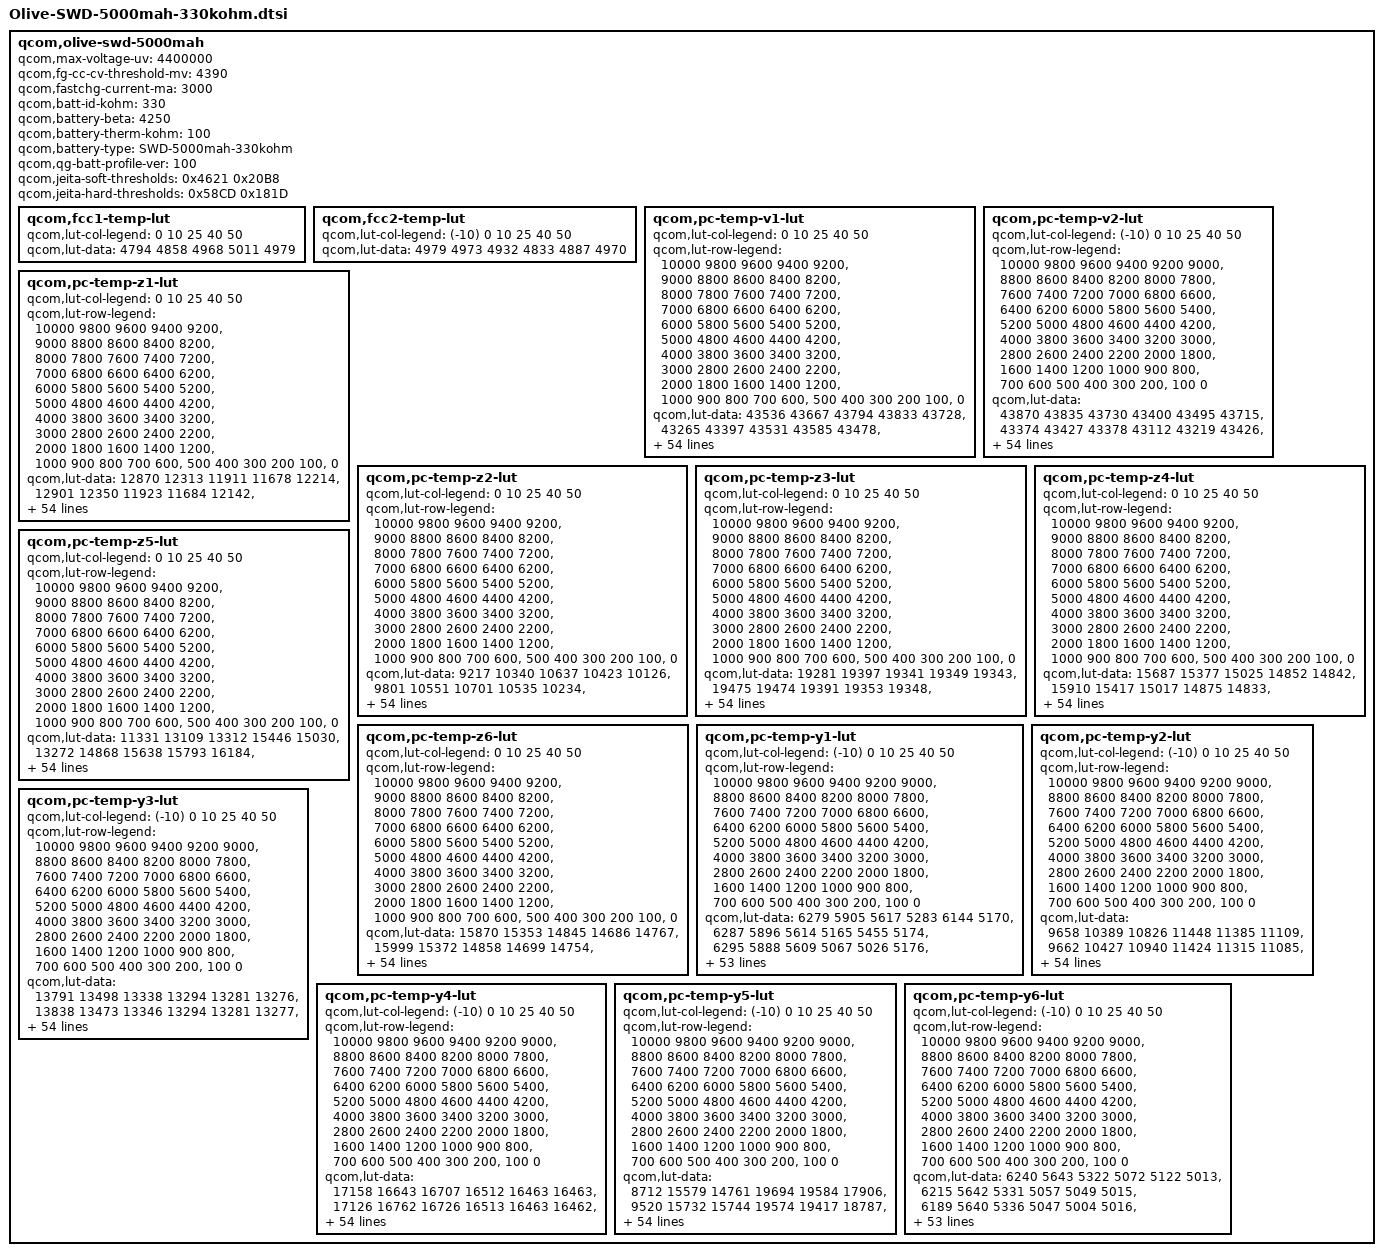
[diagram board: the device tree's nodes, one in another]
/* Copyright (c) 2018, The Linux Foundation. All rights reserved.
 * Copyright (C) 2021 XiaoMi, Inc.
 *
 * This program is free software; you can redistribute it and/or modify
 * it under the terms of the GNU General Public License version 2 and
 * only version 2 as published by the Free Software Foundation.
 *
 * This program is distributed in the hope that it will be useful,
 * but WITHOUT ANY WARRANTY; without even the implied warranty of
 * MERCHANTABILITY or FITNESS FOR A PARTICULAR PURPOSE.  See the
 * GNU General Public License for more details.
 */

qcom,olive-swd-5000mah {
	/* Peony-SWD-5000mah-300kohm_Master_2018.12.27 */
	qcom,max-voltage-uv = <4400000>;
	qcom,fg-cc-cv-threshold-mv = <4390>;
	qcom,fastchg-current-ma = <3000>;
	qcom,batt-id-kohm = <330>;
	qcom,battery-beta = <4250>;
	qcom,battery-therm-kohm = <100>;
	qcom,battery-type =
		"SWD-5000mah-330kohm";
	qcom,qg-batt-profile-ver = <100>;

/*	qcom,jeita-fcc-ranges = <0   50   400000
				 51  100  1200000
				 101 150  1950000
				 151 450  2000000
				 451 550  1000000
				 551 600  0>;
	qcom,jeita-fv-ranges =  <0   50   4400000
				 51  100  4400000
				 101 150  4400000
				 151 450  4400000
				 451 550  4100000
				 551 600  4100000>;*/

	/* COOL = 15 DegC, WARM = 45 DegC */
	qcom,jeita-soft-thresholds = <0x4621 0x20B8>;
	/* COLD = 0 DegC, HOT = 55 DegC */
	qcom,jeita-hard-thresholds = <0x58CD 0x181D>;

	qcom,fcc1-temp-lut {
		qcom,lut-col-legend = <0 10 25 40 50>;
		qcom,lut-data = <4794 4858 4968 5011 4979>;
	};

	qcom,fcc2-temp-lut {
		qcom,lut-col-legend = <(-10) 0 10 25 40 50>;
		qcom,lut-data = <4979 4973 4932 4833 4887 4970>;
	};

	qcom,pc-temp-v1-lut {
		qcom,lut-col-legend = <0 10 25 40 50>;
		qcom,lut-row-legend = <10000 9800 9600 9400 9200>,
			<9000 8800 8600 8400 8200>,
			<8000 7800 7600 7400 7200>,
			<7000 6800 6600 6400 6200>,
			<6000 5800 5600 5400 5200>,
			<5000 4800 4600 4400 4200>,
			<4000 3800 3600 3400 3200>,
			<3000 2800 2600 2400 2200>,
			<2000 1800 1600 1400 1200>,
			<1000 900 800 700 600>,
			<500 400 300 200 100>,
			<0>;
		qcom,lut-data = <43536 43667 43794 43833 43728>,
			<43265 43397 43531 43585 43478>,
			<42998 43141 43275 43332 43235>,
			<42747 42894 43027 43084 42994>,
			<42516 42655 42785 42843 42758>,
			<42297 42423 42546 42605 42524>,
			<42085 42198 42311 42369 42293>,
			<41878 41982 42081 42136 42064>,
			<41679 41772 41856 41906 41838>,
			<41490 41569 41637 41679 41613>,
			<41315 41380 41426 41454 41391>,
			<41124 41191 41231 41236 41173>,
			<40890 40983 41034 41022 40958>,
			<40630 40759 40810 40812 40752>,
			<40375 40528 40566 40601 40550>,
			<40115 40270 40340 40400 40357>,
			<39907 40020 40133 40209 40176>,
			<39775 39859 39948 40029 40002>,
			<39673 39762 39805 39862 39838>,
			<39568 39663 39691 39715 39684>,
			<39463 39522 39552 39560 39515>,
			<39353 39350 39347 39366 39310>,
			<39221 39165 39127 39152 39097>,
			<39071 38933 38948 38966 38917>,
			<38924 38735 38787 38796 38760>,
			<38772 38645 38664 38652 38629>,
			<38629 38591 38576 38545 38519>,
			<38539 38540 38503 38455 38423>,
			<38478 38486 38428 38370 38337>,
			<38431 38436 38356 38289 38260>,
			<38392 38388 38293 38217 38191>,
			<38362 38343 38237 38154 38125>,
			<38332 38301 38188 38098 38066>,
			<38305 38264 38145 38047 38010>,
			<38279 38231 38108 38004 37959>,
			<38251 38198 38071 37961 37907>,
			<38224 38170 38036 37916 37854>,
			<38187 38135 37998 37867 37797>,
			<38124 38073 37940 37803 37724>,
			<38038 37979 37852 37715 37629>,
			<37949 37874 37749 37614 37524>,
			<37856 37752 37634 37502 37409>,
			<37732 37612 37501 37371 37278>,
			<37557 37441 37336 37209 37117>,
			<37394 37274 37189 37078 37000>,
			<37284 37229 37091 36992 36923>,
			<37247 37188 37066 36963 36901>,
			<37214 37162 37044 36945 36879>,
			<37183 37131 37026 36925 36856>,
			<37127 37075 36970 36851 36765>,
			<36899 36833 36696 36555 36437>,
			<36452 36383 36253 36105 35987>,
			<35876 35802 35673 35517 35403>,
			<35097 35015 34875 34711 34600>,
			<33863 33780 33619 33443 33335>,
			<30000 30000 30000 30000 30000>;
	};

	qcom,pc-temp-v2-lut {
		qcom,lut-col-legend = <(-10) 0 10 25 40 50>;
		qcom,lut-row-legend = <10000 9800 9600 9400 9200 9000>,
			<8800 8600 8400 8200 8000 7800>,
			<7600 7400 7200 7000 6800 6600>,
			<6400 6200 6000 5800 5600 5400>,
			<5200 5000 4800 4600 4400 4200>,
			<4000 3800 3600 3400 3200 3000>,
			<2800 2600 2400 2200 2000 1800>,
			<1600 1400 1200 1000 900 800>,
			<700 600 500 400 300 200>,
			<100 0>;
		qcom,lut-data = <43870 43835 43730 43400 43495 43715>,
			<43374 43427 43378 43112 43219 43426>,
			<42942 43062 43058 42841 42956 43153>,
			<42589 42748 42773 42587 42705 42895>,
			<42298 42476 42524 42352 42468 42654>,
			<42028 42227 42285 42125 42237 42418>,
			<41705 41995 42047 41899 42007 42182>,
			<41426 41778 41813 41677 41780 41948>,
			<41356 41557 41569 41463 41557 41718>,
			<41346 41320 41296 41262 41336 41491>,
			<41332 41126 41071 41069 41119 41267>,
			<41143 41021 40946 40866 40913 41049>,
			<40763 40931 40852 40629 40717 40834>,
			<40390 40740 40688 40387 40520 40627>,
			<39972 40286 40318 40179 40307 40424>,
			<39618 39880 39954 40000 40102 40229>,
			<39405 39694 39778 39837 39926 40047>,
			<39235 39556 39659 39674 39773 39873>,
			<39044 39390 39521 39516 39620 39705>,
			<38824 39196 39346 39361 39454 39550>,
			<38641 38994 39154 39179 39269 39384>,
			<38520 38775 38955 38969 39065 39173>,
			<38425 38559 38751 38772 38854 38940>,
			<38345 38411 38572 38614 38676 38751>,
			<38277 38300 38417 38481 38534 38597>,
			<38216 38212 38282 38365 38415 38466>,
			<38159 38146 38168 38266 38312 38353>,
			<38105 38094 38071 38176 38218 38254>,
			<38052 38044 38001 38094 38133 38163>,
			<38000 37998 37952 38019 38056 38079>,
			<37948 37955 37914 37951 37989 38004>,
			<37896 37913 37880 37888 37926 37939>,
			<37843 37872 37850 37831 37867 37881>,
			<37788 37830 37820 37781 37805 37817>,
			<37734 37786 37791 37740 37739 37746>,
			<37678 37741 37758 37694 37666 37669>,
			<37617 37693 37715 37642 37587 37575>,
			<37555 37641 37656 37583 37507 37469>,
			<37483 37579 37585 37513 37431 37377>,
			<37399 37506 37498 37431 37356 37303>,
			<37309 37420 37393 37337 37275 37229>,
			<37219 37313 37278 37223 37180 37136>,
			<37131 37189 37149 37097 37071 37027>,
			<37052 37061 37027 36984 36934 36896>,
			<36982 36939 36918 36897 36837 36789>,
			<36904 36853 36826 36835 36798 36745>,
			<36861 36822 36781 36811 36782 36734>,
			<36809 36788 36733 36779 36764 36717>,
			<36735 36744 36675 36718 36726 36679>,
			<36612 36671 36574 36509 36588 36537>,
			<36359 36492 36369 36129 36226 36179>,
			<35943 36078 35963 35574 35708 35660>,
			<35351 35482 35346 34842 35040 34988>,
			<34480 34652 34500 33775 34126 34066>,
			<33086 33342 33193 32461 32685 32546>,
			<28428 29503 28960 27673 27665 28669>;
	};

	qcom,pc-temp-z1-lut {
		qcom,lut-col-legend = <0 10 25 40 50>;
		qcom,lut-row-legend = <10000 9800 9600 9400 9200>,
			<9000 8800 8600 8400 8200>,
			<8000 7800 7600 7400 7200>,
			<7000 6800 6600 6400 6200>,
			<6000 5800 5600 5400 5200>,
			<5000 4800 4600 4400 4200>,
			<4000 3800 3600 3400 3200>,
			<3000 2800 2600 2400 2200>,
			<2000 1800 1600 1400 1200>,
			<1000 900 800 700 600>,
			<500 400 300 200 100>,
			<0>;
		qcom,lut-data = <12870 12313 11911 11678 12214>,
			<12901 12350 11923 11684 12142>,
			<12907 12347 11930 11688 12066>,
			<12906 12333 11928 11687 11996>,
			<12897 12327 11921 11680 11930>,
			<12886 12317 11914 11673 11871>,
			<12883 12307 11904 11668 11817>,
			<12883 12307 11896 11664 11773>,
			<12883 12308 11892 11662 11740>,
			<12877 12306 11890 11660 11712>,
			<12851 12295 11888 11659 11680>,
			<12827 12280 11888 11661 11642>,
			<12817 12264 11888 11664 11620>,
			<12806 12246 11883 11664 11616>,
			<12794 12235 11870 11653 11612>,
			<12768 12233 11863 11644 11613>,
			<12742 12233 11864 11645 11621>,
			<12732 12236 11866 11648 11635>,
			<12724 12247 11870 11650 11663>,
			<12720 12256 11879 11652 11700>,
			<12726 12256 11883 11654 11708>,
			<12737 12252 11882 11656 11693>,
			<12739 12251 11881 11658 11681>,
			<12738 12251 11882 11660 11724>,
			<12738 12252 11885 11662 11817>,
			<12747 12257 11889 11664 11846>,
			<12762 12269 11892 11667 11826>,
			<12769 12277 11896 11671 11790>,
			<12764 12282 11900 11675 11728>,
			<12757 12286 11904 11679 11637>,
			<12758 12286 11908 11684 11607>,
			<12763 12280 11913 11686 11609>,
			<12769 12277 11916 11688 11613>,
			<12775 12286 11919 11691 11616>,
			<12782 12300 11920 11698 11620>,
			<12786 12303 11921 11703 11624>,
			<12789 12301 11927 11706 11627>,
			<12791 12298 11933 11708 11630>,
			<12794 12304 11936 11711 11633>,
			<12797 12317 11938 11716 11636>,
			<12802 12326 11941 11721 11639>,
			<12814 12332 11948 11726 11642>,
			<12827 12335 11956 11730 11646>,
			<12848 12343 11965 11735 11648>,
			<12853 12346 11968 11742 11652>,
			<12843 12359 11975 11741 11652>,
			<12828 12341 11980 11742 11652>,
			<12815 12340 11981 11745 11652>,
			<12820 12330 11986 11746 11656>,
			<12844 12350 11984 11751 11664>,
			<12883 12344 11998 11756 11770>,
			<12878 12377 12018 11763 11671>,
			<12862 12402 12017 11774 11680>,
			<12890 12410 12030 11785 11692>,
			<12890 12410 12030 11785 11692>,
			<12890 12410 12030 11785 11692>;
	};

	qcom,pc-temp-z2-lut {
		qcom,lut-col-legend = <0 10 25 40 50>;
		qcom,lut-row-legend = <10000 9800 9600 9400 9200>,
			<9000 8800 8600 8400 8200>,
			<8000 7800 7600 7400 7200>,
			<7000 6800 6600 6400 6200>,
			<6000 5800 5600 5400 5200>,
			<5000 4800 4600 4400 4200>,
			<4000 3800 3600 3400 3200>,
			<3000 2800 2600 2400 2200>,
			<2000 1800 1600 1400 1200>,
			<1000 900 800 700 600>,
			<500 400 300 200 100>,
			<0>;
		qcom,lut-data = <9217 10340 10637 10423 10126>,
			<9801 10551 10701 10535 10234>,
			<10193 10578 10732 10549 10298>,
			<10382 10590 10721 10550 10347>,
			<10374 10591 10683 10536 10391>,
			<10350 10560 10651 10518 10408>,
			<10329 10522 10623 10498 10381>,
			<10311 10500 10596 10468 10345>,
			<10295 10483 10570 10443 10305>,
			<10285 10473 10544 10418 10247>,
			<10278 10467 10535 10404 10213>,
			<10270 10462 10544 10418 10222>,
			<10248 10459 10560 10446 10242>,
			<10223 10456 10582 10459 10260>,
			<10218 10454 10614 10470 10276>,
			<10224 10468 10625 10476 10289>,
			<10234 10494 10592 10434 10300>,
			<10247 10514 10555 10356 10312>,
			<10266 10527 10557 10338 10326>,
			<10288 10542 10582 10363 10342>,
			<10318 10567 10617 10405 10375>,
			<10347 10600 10695 10526 10521>,
			<10368 10616 10768 10699 10716>,
			<10387 10623 10772 10731 10725>,
			<10402 10627 10757 10658 10576>,
			<10413 10625 10747 10602 10482>,
			<10422 10619 10742 10645 10592>,
			<10435 10616 10740 10725 10742>,
			<10452 10624 10743 10737 10725>,
			<10469 10636 10757 10681 10544>,
			<10483 10646 10764 10619 10396>,
			<10494 10657 10751 10572 10331>,
			<10507 10666 10732 10532 10290>,
			<10519 10671 10727 10522 10287>,
			<10533 10677 10726 10525 10312>,
			<10548 10684 10725 10531 10344>,
			<10564 10693 10740 10551 10383>,
			<10583 10705 10767 10587 10426>,
			<10601 10729 10796 10627 10464>,
			<10627 10761 10836 10686 10501>,
			<10720 10775 10855 10727 10526>,
			<11057 10777 10840 10731 10536>,
			<11115 10781 10825 10726 10539>,
			<10669 10803 10821 10720 10560>,
			<11197 10917 10862 10678 10550>,
			<11219 14594 10888 10612 10482>,
			<11242 19042 10870 10625 10511>,
			<11071 28538 10861 10639 10505>,
			<11192 30624 10848 10662 10568>,
			<11378 28614 10876 10731 10638>,
			<11138 26924 10914 10604 10420>,
			<10684 25427 10830 10483 10333>,
			<10564 22818 10775 10455 10296>,
			<10316 22379 10719 10386 10238>,
			<10316 22379 10719 10386 10238>,
			<10316 22379 10719 10386 10238>;
	};

	qcom,pc-temp-z3-lut {
		qcom,lut-col-legend = <0 10 25 40 50>;
		qcom,lut-row-legend = <10000 9800 9600 9400 9200>,
			<9000 8800 8600 8400 8200>,
			<8000 7800 7600 7400 7200>,
			<7000 6800 6600 6400 6200>,
			<6000 5800 5600 5400 5200>,
			<5000 4800 4600 4400 4200>,
			<4000 3800 3600 3400 3200>,
			<3000 2800 2600 2400 2200>,
			<2000 1800 1600 1400 1200>,
			<1000 900 800 700 600>,
			<500 400 300 200 100>,
			<0>;
		qcom,lut-data = <19281 19397 19341 19349 19343>,
			<19475 19474 19391 19353 19348>,
			<19612 19512 19423 19375 19360>,
			<19682 19538 19432 19386 19370>,
			<19690 19547 19437 19391 19377>,
			<19695 19549 19439 19394 19381>,
			<19695 19550 19439 19394 19382>,
			<19690 19550 19439 19395 19382>,
			<19686 19548 19439 19394 19381>,
			<19683 19546 19437 19392 19378>,
			<19679 19544 19435 19389 19375>,
			<19676 19541 19432 19388 19374>,
			<19678 19537 19429 19388 19372>,
			<19684 19530 19429 19387 19370>,
			<19688 19525 19430 19383 19369>,
			<19691 19522 19430 19379 19366>,
			<19688 19519 19426 19374 19362>,
			<19673 19514 19419 19369 19357>,
			<19651 19501 19413 19364 19353>,
			<19634 19492 19405 19359 19349>,
			<19620 19494 19402 19356 19347>,
			<19610 19501 19406 19360 19353>,
			<19612 19504 19411 19367 19361>,
			<19622 19505 19410 19368 19361>,
			<19627 19505 19405 19362 19354>,
			<19626 19504 19402 19357 19350>,
			<19624 19499 19404 19364 19367>,
			<19622 19496 19407 19377 19389>,
			<19618 19497 19413 19385 19392>,
			<19614 19497 19424 19391 19387>,
			<19608 19498 19429 19394 19381>,
			<19602 19499 19428 19392 19376>,
			<19596 19500 19426 19387 19370>,
			<19590 19498 19422 19381 19365>,
			<19583 19494 19418 19375 19358>,
			<19578 19491 19413 19369 19353>,
			<19572 19486 19408 19364 19349>,
			<19567 19482 19404 19361 19345>,
			<19564 19479 19402 19359 19344>,
			<19560 19475 19400 19359 19345>,
			<19523 19471 19399 19359 19345>,
			<19330 19467 19396 19359 19347>,
			<19259 19462 19392 19358 19350>,
			<19260 19456 19388 19359 19352>,
			<19258 19440 19378 19352 19347>,
			<19258 19257 19374 19342 19340>,
			<19258 19257 19369 19341 19328>,
			<19259 19256 19367 19334 19327>,
			<19258 19256 19363 19330 19321>,
			<19258 19256 19350 19325 19319>,
			<19258 19256 19365 19343 19344>,
			<19259 19256 19361 19349 19346>,
			<19259 19256 19350 19348 19342>,
			<19260 19256 19346 19347 19343>,
			<19260 19256 19346 19347 19343>,
			<19260 19256 19346 19347 19343>;
	};

	qcom,pc-temp-z4-lut {
		qcom,lut-col-legend = <0 10 25 40 50>;
		qcom,lut-row-legend = <10000 9800 9600 9400 9200>,
			<9000 8800 8600 8400 8200>,
			<8000 7800 7600 7400 7200>,
			<7000 6800 6600 6400 6200>,
			<6000 5800 5600 5400 5200>,
			<5000 4800 4600 4400 4200>,
			<4000 3800 3600 3400 3200>,
			<3000 2800 2600 2400 2200>,
			<2000 1800 1600 1400 1200>,
			<1000 900 800 700 600>,
			<500 400 300 200 100>,
			<0>;
		qcom,lut-data = <15687 15377 15025 14852 14842>,
			<15910 15417 15017 14875 14833>,
			<15745 15357 14998 14853 14818>,
			<15549 15207 14964 14832 14802>,
			<15405 15092 14907 14808 14784>,
			<15277 15015 14862 14785 14766>,
			<15176 14951 14830 14767 14751>,
			<15097 14899 14804 14750 14737>,
			<15031 14856 14782 14735 14724>,
			<14974 14823 14763 14720 14712>,
			<14921 14800 14747 14709 14704>,
			<14883 14780 14733 14705 14699>,
			<14856 14760 14722 14703 14695>,
			<14838 14739 14717 14700 14691>,
			<14835 14728 14713 14695 14687>,
			<14839 14740 14710 14691 14683>,
			<14842 14760 14707 14687 14679>,
			<14827 14760 14704 14682 14675>,
			<14794 14728 14696 14678 14671>,
			<14768 14702 14681 14671 14666>,
			<14746 14704 14676 14668 14665>,
			<14732 14714 14704 14681 14682>,
			<14731 14732 14746 14711 14713>,
			<14735 14791 14776 14739 14738>,
			<14742 14846 14803 14768 14761>,
			<14768 14846 14813 14784 14769>,
			<14804 14829 14803 14771 14744>,
			<14811 14811 14785 14743 14707>,
			<14804 14795 14768 14724 14694>,
			<14794 14780 14749 14708 14690>,
			<14784 14768 14737 14698 14686>,
			<14771 14758 14731 14694 14682>,
			<14758 14751 14726 14691 14679>,
			<14747 14745 14724 14689 14677>,
			<14737 14740 14723 14688 14676>,
			<14728 14735 14722 14688 14676>,
			<14718 14727 14719 14688 14676>,
			<14711 14722 14717 14688 14677>,
			<14706 14721 14716 14689 14680>,
			<14703 14721 14716 14693 14687>,
			<14732 14720 14716 14695 14691>,
			<14919 14710 14707 14688 14684>,
			<14988 14699 14695 14680 14677>,
			<14969 14691 14689 14678 14678>,
			<14899 14668 14670 14668 14665>,
			<14883 14826 14656 14655 14650>,
			<14875 14821 14650 14649 14652>,
			<14871 14812 14642 14641 14637>,
			<14864 14807 14635 14629 14625>,
			<14859 14803 14643 14631 14624>,
			<14866 14810 14645 14641 14639>,
			<14881 14818 14653 14642 14645>,
			<14890 14821 14667 14645 14652>,
			<14897 14825 14673 14649 14653>,
			<14897 14825 14673 14649 14653>,
			<14897 14825 14673 14649 14653>;
	};

	qcom,pc-temp-z5-lut {
		qcom,lut-col-legend = <0 10 25 40 50>;
		qcom,lut-row-legend = <10000 9800 9600 9400 9200>,
			<9000 8800 8600 8400 8200>,
			<8000 7800 7600 7400 7200>,
			<7000 6800 6600 6400 6200>,
			<6000 5800 5600 5400 5200>,
			<5000 4800 4600 4400 4200>,
			<4000 3800 3600 3400 3200>,
			<3000 2800 2600 2400 2200>,
			<2000 1800 1600 1400 1200>,
			<1000 900 800 700 600>,
			<500 400 300 200 100>,
			<0>;
		qcom,lut-data = <11331 13109 13312 15446 15030>,
			<13272 14868 15638 15793 16184>,
			<14969 16349 17370 17889 18124>,
			<16161 17671 18358 19239 19851>,
			<16883 18853 19041 19998 21171>,
			<17446 19848 19702 20617 22058>,
			<17993 20848 20356 21162 22558>,
			<18510 22068 21023 21656 22979>,
			<19090 23470 21766 22239 23500>,
			<20045 24993 22578 22957 24064>,
			<21227 26783 23530 23696 24623>,
			<21993 28562 24642 24418 25227>,
			<23222 30046 26039 25158 25934>,
			<24974 31575 28495 25911 26918>,
			<26222 32325 32068 27038 28141>,
			<28485 31523 33348 27754 28704>,
			<29556 30184 30727 26911 28481>,
			<28323 29875 27808 25272 28202>,
			<26610 30166 28778 25016 28377>,
			<26184 30746 33104 26550 29152>,
			<27000 37509 36611 28579 30313>,
			<28655 51133 39010 30841 33054>,
			<34193 55700 40594 33107 36416>,
			<46981 53013 38616 32692 34802>,
			<54927 48812 31174 26079 25887>,
			<56890 43979 26797 21041 20561>,
			<57816 37968 25868 21400 23805>,
			<57105 35497 25376 22486 28529>,
			<54512 35728 26424 24148 29677>,
			<51660 36232 30930 27775 29829>,
			<49454 37336 35076 31216 30067>,
			<47362 40240 37985 33401 30900>,
			<45875 43117 40319 35061 31862>,
			<44865 45380 41680 35548 32237>,
			<44146 47262 42692 35674 32490>,
			<43797 47911 43068 35673 32613>,
			<43904 48161 42434 35379 32378>,
			<44406 48271 41256 34783 31827>,
			<46314 48098 40207 34083 31104>,
			<48785 47528 39150 33025 29928>,
			<45471 46554 37829 31951 29248>,
			<20928 43578 35636 30897 29692>,
			<11699 41356 33593 30258 30733>,
			<11745 40389 32196 31133 33225>,
			<12034 43502 33554 29619 32357>,
			<12031 12116 34749 26020 27877>,
			<11982 12068 32230 26131 21471>,
			<11967 11934 33336 25111 24037>,
			<11942 11911 34091 27613 27200>,
			<11924 11955 24783 24326 26291>,
			<11984 11957 28315 26291 31844>,
			<11885 11854 24278 26279 27085>,
			<11771 11770 18837 23571 21719>,
			<11652 11668 17452 20868 19433>,
			<11652 11668 17452 20868 19433>,
			<11652 11668 17452 20868 19433>;
	};

	qcom,pc-temp-z6-lut {
		qcom,lut-col-legend = <0 10 25 40 50>;
		qcom,lut-row-legend = <10000 9800 9600 9400 9200>,
			<9000 8800 8600 8400 8200>,
			<8000 7800 7600 7400 7200>,
			<7000 6800 6600 6400 6200>,
			<6000 5800 5600 5400 5200>,
			<5000 4800 4600 4400 4200>,
			<4000 3800 3600 3400 3200>,
			<3000 2800 2600 2400 2200>,
			<2000 1800 1600 1400 1200>,
			<1000 900 800 700 600>,
			<500 400 300 200 100>,
			<0>;
		qcom,lut-data = <15870 15353 14845 14686 14767>,
			<15999 15372 14858 14699 14754>,
			<15925 15341 14862 14699 14741>,
			<15825 15260 14852 14697 14727>,
			<15733 15193 14823 14689 14711>,
			<15639 15141 14800 14678 14696>,
			<15563 15096 14783 14670 14682>,
			<15499 15058 14768 14662 14669>,
			<15446 15025 14755 14654 14657>,
			<15400 14998 14744 14646 14645>,
			<15359 14978 14735 14640 14635>,
			<15322 14961 14726 14638 14625>,
			<15289 14938 14720 14637 14618>,
			<15264 14910 14714 14635 14614>,
			<15250 14896 14710 14629 14611>,
			<15240 14898 14706 14623 14609>,
			<15230 14901 14703 14618 14606>,
			<15207 14899 14699 14614 14604>,
			<15177 14881 14693 14610 14603>,
			<15155 14867 14685 14605 14604>,
			<15139 14870 14682 14602 14606>,
			<15128 14879 14697 14610 14614>,
			<15130 14893 14718 14627 14629>,
			<15139 14921 14731 14639 14647>,
			<15149 14945 14742 14649 14668>,
			<15162 14945 14746 14655 14675>,
			<15177 14937 14743 14653 14670>,
			<15179 14930 14738 14649 14661>,
			<15176 14924 14736 14646 14647>,
			<15172 14919 14734 14644 14627>,
			<15167 14915 14733 14641 14616>,
			<15159 14913 14731 14638 14612>,
			<15153 14911 14729 14635 14609>,
			<15147 14909 14727 14632 14605>,
			<15142 14907 14725 14629 14602>,
			<15138 14905 14723 14626 14599>,
			<15134 14903 14721 14624 14597>,
			<15133 14902 14720 14623 14596>,
			<15135 14903 14720 14623 14596>,
			<15138 14906 14722 14625 14600>,
			<15138 14907 14723 14626 14602>,
			<15133 14905 14720 14624 14601>,
			<15131 14904 14715 14621 14599>,
			<15134 14903 14714 14621 14601>,
			<15120 14896 14705 14615 14594>,
			<15114 14879 14699 14604 14584>,
			<15110 14876 14694 14601 14578>,
			<15108 14873 14692 14594 14571>,
			<15106 14871 14687 14587 14563>,
			<15109 14875 14686 14586 14563>,
			<15118 14884 14699 14602 14602>,
			<15131 14894 14704 14608 14589>,
			<15144 14902 14708 14611 14592>,
			<15163 14915 14715 14615 14596>,
			<15163 14915 14715 14615 14596>,
			<15163 14915 14715 14615 14596>;
	};

	qcom,pc-temp-y1-lut {
		qcom,lut-col-legend = <(-10) 0 10 25 40 50>;
		qcom,lut-row-legend = <10000 9800 9600 9400 9200 9000>,
			<8800 8600 8400 8200 8000 7800>,
			<7600 7400 7200 7000 6800 6600>,
			<6400 6200 6000 5800 5600 5400>,
			<5200 5000 4800 4600 4400 4200>,
			<4000 3800 3600 3400 3200 3000>,
			<2800 2600 2400 2200 2000 1800>,
			<1600 1400 1200 1000 900 800>,
			<700 600 500 400 300 200>,
			<100 0>;
		qcom,lut-data = <6279 5905 5617 5283 6144 5170>,
			<6287 5896 5614 5165 5455 5174>,
			<6295 5888 5609 5067 5026 5176>,
			<6300 5881 5604 4990 4795 5177>,
			<6304 5877 5600 4938 4700 5178>,
			<6305 5875 5598 4914 4681 5177>,
			<6308 5873 5598 4923 4800 5081>,
			<6311 5871 5597 4959 5097 4919>,
			<6308 5873 5597 4996 5223 4873>,
			<6293 5883 5597 5019 5222 4863>,
			<6286 5889 5598 5043 5221 4860>,
			<6297 5889 5632 5084 5220 4956>,
			<6311 5888 5688 5177 5218 5126>,
			<6316 5888 5694 5255 5216 5152>,
			<6327 5889 5641 5261 5216 5045>,
			<6335 5889 5601 5259 5218 4964>,
			<6328 5886 5604 5260 5219 5024>,
			<6312 5883 5608 5248 5219 5137>,
			<6305 5882 5609 5227 5219 5153>,
			<6298 5885 5608 5224 5219 5040>,
			<6297 5889 5607 5265 5219 4949>,
			<6305 5891 5605 5308 5221 5009>,
			<6316 5892 5602 5294 5222 5133>,
			<6323 5890 5601 5231 5223 5161>,
			<6324 5880 5602 5195 5225 5084>,
			<6320 5872 5605 5200 5227 5019>,
			<6315 5872 5610 5212 5229 5060>,
			<6311 5873 5619 5233 5231 5150>,
			<6316 5874 5621 5298 5234 5168>,
			<6325 5876 5619 5360 5237 5051>,
			<6332 5877 5616 5372 5239 4946>,
			<6325 5877 5616 5376 5243 5002>,
			<6309 5878 5615 5380 5245 5141>,
			<6299 5879 5613 5385 5248 5178>,
			<6294 5884 5613 5390 5249 5019>,
			<6290 5890 5614 5394 5252 4867>,
			<6290 5888 5615 5398 5254 4936>,
			<6294 5881 5616 5400 5256 5127>,
			<6297 5877 5616 5403 5257 5191>,
			<6299 5878 5618 5407 5257 5093>,
			<6302 5881 5618 5410 5258 4998>,
			<6304 5888 5616 5411 5259 4996>,
			<6300 5893 5611 5411 5262 5014>,
			<6307 5891 5613 5417 5267 5116>,
			<6322 5883 5617 5422 5272 5209>,
			<6303 5879 5624 5424 5275 5211>,
			<6338 5906 5631 5430 5276 5210>,
			<6360 5895 5624 5431 5275 5210>,
			<6327 5918 5623 5427 5273 5209>,
			<6336 5917 5633 5429 5272 5073>,
			<6372 5914 5627 5429 5274 4880>,
			<6351 5923 5638 5428 5282 5068>,
			<6363 5949 5660 5447 5291 5224>,
			<6446 5945 5680 5463 5301 5231>,
			<6446 5945 5680 5463 5301 5231>,
			<6446 5945 5680 5463 5301 5231>;
	};

	qcom,pc-temp-y2-lut {
		qcom,lut-col-legend = <(-10) 0 10 25 40 50>;
		qcom,lut-row-legend = <10000 9800 9600 9400 9200 9000>,
			<8800 8600 8400 8200 8000 7800>,
			<7600 7400 7200 7000 6800 6600>,
			<6400 6200 6000 5800 5600 5400>,
			<5200 5000 4800 4600 4400 4200>,
			<4000 3800 3600 3400 3200 3000>,
			<2800 2600 2400 2200 2000 1800>,
			<1600 1400 1200 1000 900 800>,
			<700 600 500 400 300 200>,
			<100 0>;
		qcom,lut-data = <9658 10389 10826 11448 11385 11109>,
			<9662 10427 10940 11424 11315 11085>,
			<9665 10461 11019 11398 11241 11062>,
			<9668 10489 11069 11371 11168 11038>,
			<9671 10507 11095 11344 11106 11015>,
			<9671 10515 11102 11319 11062 10992>,
			<9670 10554 11078 11295 11032 10967>,
			<9669 10608 11030 11272 11009 10943>,
			<9669 10592 11006 11252 10998 10933>,
			<9670 10508 10975 11225 10993 10929>,
			<9670 10472 10964 11194 10990 10925>,
			<9671 10573 11057 11168 10995 10911>,
			<9671 10713 11222 11165 11012 10894>,
			<9671 10694 11286 11195 11030 10891>,
			<9670 10518 11281 11246 11042 10897>,
			<9668 10423 11275 11300 11058 10909>,
			<9668 10438 11316 11348 11097 10930>,
			<9668 10448 11410 11411 11174 10965>,
			<9668 10447 11464 11488 11253 11011>,
			<9668 10441 11478 11566 11327 11089>,
			<9667 10436 11479 11599 11375 11157>,
			<9667 10272 11461 11571 11363 11192>,
			<9666 9880 11430 11533 11313 11218>,
			<9666 9723 11400 11524 11281 11226>,
			<9666 9708 11375 11527 11283 11221>,
			<9665 9699 11339 11541 11296 11215>,
			<9665 9695 11160 11573 11321 11214>,
			<9665 9692 10662 11604 11362 11218>,
			<9665 9688 10348 11621 11403 11236>,
			<9665 9684 10473 11630 11440 11305>,
			<9664 9680 10760 11633 11483 11369>,
			<9664 9678 10912 11636 11522 11389>,
			<9664 9675 11051 11638 11537 11401>,
			<9664 9673 11066 11616 11524 11402>,
			<9663 9671 11009 11567 11503 11383>,
			<9663 9669 10927 11531 11478 11360>,
			<9663 9668 10687 11512 11451 11338>,
			<9663 9666 10111 11495 11429 11304>,
			<9663 9665 9752 11464 11413 11281>,
			<9662 9665 9710 11408 11396 11246>,
			<9662 9664 9694 11343 11384 11215>,
			<9662 9663 9685 11271 11384 11209>,
			<9662 9663 9679 11191 11372 11205>,
			<9662 9662 9675 11127 11268 11168>,
			<9661 9661 9671 11046 11163 11070>,
			<9661 9661 9669 11019 11124 10954>,
			<9661 9661 9669 11020 11118 10945>,
			<9660 9660 9669 11005 11177 10988>,
			<9660 9660 9669 10990 11214 11019>,
			<9659 9660 9668 10933 11201 10971>,
			<9659 9659 9667 10875 11129 10940>,
			<9659 9659 9665 10826 11052 10856>,
			<9658 9658 9662 10755 10935 10764>,
			<9655 9657 9660 10682 10888 10614>,
			<9655 9657 9660 10682 10888 10614>,
			<9655 9657 9660 10682 10888 10614>;
	};

	qcom,pc-temp-y3-lut {
		qcom,lut-col-legend = <(-10) 0 10 25 40 50>;
		qcom,lut-row-legend = <10000 9800 9600 9400 9200 9000>,
			<8800 8600 8400 8200 8000 7800>,
			<7600 7400 7200 7000 6800 6600>,
			<6400 6200 6000 5800 5600 5400>,
			<5200 5000 4800 4600 4400 4200>,
			<4000 3800 3600 3400 3200 3000>,
			<2800 2600 2400 2200 2000 1800>,
			<1600 1400 1200 1000 900 800>,
			<700 600 500 400 300 200>,
			<100 0>;
		qcom,lut-data = <13791 13498 13338 13294 13281 13276>,
			<13838 13473 13346 13294 13281 13277>,
			<13852 13459 13352 13295 13281 13278>,
			<13839 13452 13358 13296 13281 13279>,
			<13807 13451 13362 13297 13282 13280>,
			<13764 13452 13363 13298 13282 13280>,
			<13682 13466 13362 13299 13283 13281>,
			<13593 13486 13359 13300 13284 13281>,
			<13574 13480 13358 13302 13284 13282>,
			<13574 13425 13360 13303 13284 13282>,
			<13575 13387 13362 13305 13285 13283>,
			<13590 13387 13356 13306 13286 13283>,
			<13612 13392 13345 13305 13287 13283>,
			<13609 13393 13340 13304 13288 13283>,
			<13566 13393 13343 13303 13288 13283>,
			<13535 13394 13346 13304 13287 13283>,
			<13542 13394 13343 13305 13288 13284>,
			<13555 13392 13338 13304 13290 13286>,
			<13557 13387 13336 13302 13291 13287>,
			<13549 13380 13332 13301 13291 13288>,
			<13543 13374 13327 13298 13290 13288>,
			<13548 13364 13322 13295 13287 13286>,
			<13562 13352 13317 13292 13283 13282>,
			<13577 13349 13313 13290 13280 13279>,
			<13592 13341 13310 13289 13279 13278>,
			<13610 13334 13308 13288 13279 13277>,
			<13629 13341 13297 13288 13279 13277>,
			<13651 13354 13273 13288 13278 13277>,
			<13675 13366 13261 13288 13278 13277>,
			<13701 13384 13267 13287 13278 13277>,
			<13729 13405 13279 13287 13278 13276>,
			<13758 13426 13290 13287 13278 13276>,
			<13788 13447 13306 13287 13278 13276>,
			<13817 13470 13314 13287 13278 13276>,
			<13847 13495 13318 13287 13279 13277>,
			<13878 13522 13321 13287 13279 13277>,
			<13911 13555 13329 13289 13279 13277>,
			<13945 13591 13344 13291 13278 13277>,
			<13980 13628 13359 13292 13279 13277>,
			<14012 13666 13370 13293 13280 13278>,
			<14044 13705 13380 13294 13281 13280>,
			<14075 13741 13395 13295 13282 13280>,
			<14110 13778 13418 13296 13283 13281>,
			<14155 13825 13449 13299 13282 13280>,
			<14219 13879 13496 13304 13282 13279>,
			<14252 13908 13543 13310 13288 13283>,
			<14276 13916 13541 13316 13290 13285>,
			<14329 13964 13537 13324 13294 13287>,
			<14404 14011 13567 13328 13295 13287>,
			<14478 14063 13589 13328 13290 13285>,
			<14562 14114 13611 13324 13288 13283>,
			<14658 14172 13645 13320 13289 13285>,
			<14824 14294 13753 13331 13294 13290>,
			<15299 14443 13941 13354 13302 13295>,
			<15299 14443 13941 13354 13302 13295>,
			<15299 14443 13941 13354 13302 13295>;
	};

	qcom,pc-temp-y4-lut {
		qcom,lut-col-legend = <(-10) 0 10 25 40 50>;
		qcom,lut-row-legend = <10000 9800 9600 9400 9200 9000>,
			<8800 8600 8400 8200 8000 7800>,
			<7600 7400 7200 7000 6800 6600>,
			<6400 6200 6000 5800 5600 5400>,
			<5200 5000 4800 4600 4400 4200>,
			<4000 3800 3600 3400 3200 3000>,
			<2800 2600 2400 2200 2000 1800>,
			<1600 1400 1200 1000 900 800>,
			<700 600 500 400 300 200>,
			<100 0>;
		qcom,lut-data = <17158 16643 16707 16512 16463 16463>,
			<17126 16762 16726 16513 16463 16462>,
			<17111 16851 16753 16514 16463 16460>,
			<17111 16913 16782 16515 16463 16458>,
			<17121 16951 16806 16516 16463 16456>,
			<17140 16967 16817 16517 16463 16455>,
			<17194 16945 16818 16517 16463 16455>,
			<17291 16908 16817 16518 16463 16455>,
			<17412 16931 16810 16520 16464 16455>,
			<17599 17075 16782 16526 16466 16456>,
			<17706 17177 16761 16533 16469 16456>,
			<17589 17238 16852 16535 16473 16458>,
			<17348 17327 17037 16530 16480 16460>,
			<17159 17302 17076 16525 16487 16463>,
			<16985 17030 16890 16532 16490 16467>,
			<16868 16829 16722 16554 16494 16471>,
			<16826 16839 16740 16576 16501 16476>,
			<16798 16862 16806 16594 16515 16481>,
			<16761 16862 16830 16610 16529 16491>,
			<16712 16818 16810 16622 16540 16512>,
			<16678 16761 16775 16606 16542 16527>,
			<16669 16694 16727 16565 16528 16515>,
			<16663 16624 16661 16525 16498 16489>,
			<16662 16603 16608 16502 16474 16473>,
			<16663 16599 16563 16489 16464 16462>,
			<16664 16598 16533 16484 16460 16456>,
			<16665 16598 16536 16483 16460 16456>,
			<16666 16601 16558 16483 16461 16456>,
			<16668 16603 16576 16483 16465 16456>,
			<16673 16605 16573 16484 16470 16461>,
			<16680 16608 16560 16484 16477 16467>,
			<16686 16614 16550 16481 16484 16476>,
			<16693 16624 16544 16478 16488 16486>,
			<16699 16635 16551 16480 16488 16489>,
			<16706 16647 16572 16484 16485 16489>,
			<16713 16658 16597 16489 16477 16488>,
			<16719 16666 16620 16491 16466 16480>,
			<16724 16674 16642 16494 16460 16460>,
			<16724 16678 16657 16498 16459 16453>,
			<16718 16678 16665 16506 16463 16461>,
			<16713 16677 16670 16514 16470 16470>,
			<16713 16673 16673 16523 16477 16476>,
			<16715 16665 16675 16533 16480 16479>,
			<16728 16655 16682 16544 16472 16465>,
			<16751 16648 16699 16562 16469 16452>,
			<16760 16647 16725 16584 16489 16471>,
			<16762 16652 16731 16617 16509 16496>,
			<16785 16672 16749 16661 16550 16528>,
			<16811 16702 16806 16688 16574 16555>,
			<16834 16741 16868 16683 16544 16534>,
			<16820 16760 16896 16642 16493 16481>,
			<16804 16728 16880 16607 16491 16475>,
			<16805 16719 16870 16639 16506 16479>,
			<16945 16734 16906 16725 16545 16506>,
			<16945 16734 16906 16725 16545 16506>,
			<16945 16734 16906 16725 16545 16506>;
	};

	qcom,pc-temp-y5-lut {
		qcom,lut-col-legend = <(-10) 0 10 25 40 50>;
		qcom,lut-row-legend = <10000 9800 9600 9400 9200 9000>,
			<8800 8600 8400 8200 8000 7800>,
			<7600 7400 7200 7000 6800 6600>,
			<6400 6200 6000 5800 5600 5400>,
			<5200 5000 4800 4600 4400 4200>,
			<4000 3800 3600 3400 3200 3000>,
			<2800 2600 2400 2200 2000 1800>,
			<1600 1400 1200 1000 900 800>,
			<700 600 500 400 300 200>,
			<100 0>;
		qcom,lut-data = <8712 15579 14761 19694 19584 17906>,
			<9520 15732 15744 19574 19417 18787>,
			<12517 15983 16796 19521 19169 19564>,
			<14307 16316 17756 19508 18891 20186>,
			<15173 16715 18465 19514 18635 20604>,
			<15401 17167 18762 19513 18456 20765>,
			<14266 18942 18676 19524 18350 20630>,
			<12442 21318 18416 19592 18237 20346>,
			<12437 21002 17819 19552 18037 20095>,
			<15016 16535 15807 18803 17553 19687>,
			<18376 13450 14295 17714 17067 19195>,
			<22687 15834 14817 17180 16904 18662>,
			<27024 20008 16217 17145 16918 18066>,
			<26745 21279 17224 17335 16815 17460>,
			<19669 20109 18637 17292 16237 16743>,
			<14585 19318 19507 17076 15614 16336>,
			<15744 19917 19256 16806 15536 16442>,
			<17846 20926 19209 16815 15752 16658>,
			<17969 21757 19884 17392 16119 16745>,
			<15608 22852 21493 18654 17069 16765>,
			<13671 23511 22999 20408 18751 16794>,
			<13311 21625 23624 22162 19995 17869>,
			<13124 18147 24015 23344 20695 20005>,
			<13072 16354 24482 23567 20819 20810>,
			<13054 14501 25252 23375 20886 20999>,
			<13048 13117 25871 23218 20921 21082>,
			<13161 13062 23625 23207 20613 20929>,
			<13409 13208 16501 23241 19742 20467>,
			<13588 13305 12761 23477 18908 19801>,
			<13705 13528 13489 23785 18544 18391>,
			<13801 13792 15023 23893 18585 17336>,
			<13881 13993 16115 23876 19030 17432>,
			<13960 14177 17686 23790 19936 17880>,
			<14077 14230 18501 23256 21121 18664>,
			<14264 14290 18797 22298 22215 21082>,
			<14415 14410 18923 21849 22729 23238>,
			<14569 14690 18663 21868 22477 23444>,
			<14797 15107 17746 21917 21949 23221>,
			<14881 15406 16884 21565 21531 23244>,
			<14730 15653 16321 20240 21347 23551>,
			<14481 15775 15822 18890 21425 23835>,
			<14101 15412 15422 17910 21530 23910>,
			<13714 14935 15119 17167 21287 23793>,
			<13517 14813 14813 16999 19795 22935>,
			<13669 14572 14616 16853 18385 20744>,
			<13688 14465 14765 17072 18347 18482>,
			<13882 14375 14995 17209 17948 17872>,
			<13969 14210 15538 17057 17377 16879>,
			<14195 14159 16093 16865 17194 16323>,
			<14468 14386 16517 16882 17789 16341>,
			<14608 14759 16771 17201 18855 17104>,
			<14194 14356 16153 18431 18986 18180>,
			<14170 14301 14896 18923 19872 19975>,
			<12717 14044 13807 20534 23137 22970>,
			<12717 14044 13807 20534 23137 22970>,
			<12717 14044 13807 20534 23137 22970>;
	};

	qcom,pc-temp-y6-lut {
		qcom,lut-col-legend = <(-10) 0 10 25 40 50>;
		qcom,lut-row-legend = <10000 9800 9600 9400 9200 9000>,
			<8800 8600 8400 8200 8000 7800>,
			<7600 7400 7200 7000 6800 6600>,
			<6400 6200 6000 5800 5600 5400>,
			<5200 5000 4800 4600 4400 4200>,
			<4000 3800 3600 3400 3200 3000>,
			<2800 2600 2400 2200 2000 1800>,
			<1600 1400 1200 1000 900 800>,
			<700 600 500 400 300 200>,
			<100 0>;
		qcom,lut-data = <6240 5643 5322 5072 5122 5013>,
			<6215 5642 5331 5057 5049 5015>,
			<6189 5640 5336 5047 5004 5016>,
			<6163 5637 5339 5039 4980 5016>,
			<6136 5635 5340 5035 4970 5017>,
			<6108 5633 5340 5033 4968 5017>,
			<6072 5630 5337 5034 4981 5007>,
			<6040 5627 5330 5038 5013 4991>,
			<6043 5625 5321 5043 5027 4986>,
			<6091 5621 5309 5048 5028 4985>,
			<6124 5620 5301 5054 5029 4985>,
			<6100 5640 5321 5059 5030 4996>,
			<6046 5674 5361 5065 5033 5015>,
			<5988 5669 5369 5071 5036 5019>,
			<5914 5588 5321 5077 5037 5009>,
			<5868 5529 5276 5083 5037 5002>,
			<5863 5534 5280 5088 5040 5010>,
			<5861 5542 5296 5091 5045 5025>,
			<5854 5543 5303 5092 5050 5029>,
			<5839 5532 5295 5094 5053 5023>,
			<5828 5517 5283 5093 5052 5017>,
			<5832 5498 5267 5084 5046 5019>,
			<5841 5476 5246 5068 5034 5021>,
			<5852 5470 5231 5053 5026 5019>,
			<5864 5475 5221 5045 5023 5007>,
			<5878 5482 5215 5044 5022 4996>,
			<5894 5493 5212 5046 5022 5001>,
			<5911 5511 5211 5049 5022 5011>,
			<5930 5530 5211 5056 5023 5013>,
			<5951 5551 5218 5064 5024 5001>,
			<5974 5573 5232 5065 5027 4990>,
			<5997 5597 5246 5066 5029 4998>,
			<6021 5622 5264 5066 5031 5017>,
			<6046 5649 5285 5068 5031 5022>,
			<6072 5678 5308 5070 5031 5006>,
			<6098 5709 5334 5073 5029 4991>,
			<6125 5741 5360 5076 5026 4995>,
			<6152 5774 5388 5080 5024 5009>,
			<6178 5807 5417 5083 5025 5014>,
			<6202 5841 5445 5088 5027 5007>,
			<6226 5874 5475 5094 5030 5001>,
			<6252 5904 5509 5100 5033 5002>,
			<6284 5935 5548 5108 5035 5005>,
			<6325 5970 5593 5118 5033 5011>,
			<6384 6013 5649 5134 5032 5018>,
			<6417 6036 5701 5150 5044 5026>,
			<6440 6048 5701 5167 5052 5035>,
			<6492 6091 5700 5189 5066 5045>,
			<6556 6138 5739 5201 5073 5053>,
			<6623 6192 5777 5201 5060 5031>,
			<6694 6238 5805 5188 5044 4995>,
			<6776 6282 5838 5175 5046 5013>,
			<6920 6380 5942 5206 5056 5036>,
			<7373 6509 6115 5263 5075 5049>,
			<7373 6509 6115 5263 5075 5049>,
			<7373 6509 6115 5263 5075 5049>;
	};

};
